# ATSAMG55G19 register map
Vendor: Atmel; Series: SAMG55; File version: 0
CPU: CM4 r0p1, selectable endian, MPU, FPU, 4 interrupt priority bits
Registers are 32-bit, read-write, reset 0x0 unless marked. A register's access mark holds for its fields unless they carry their own. Offsets are from the block's base; [hi:lo] are bit positions; {n}, {i} and the like mark numbered series; 'fields as' and 'values as' point back to an identical list.

## TC0 — Timer Counter 0
Base 0x40010000; register names take the prefix TC0_
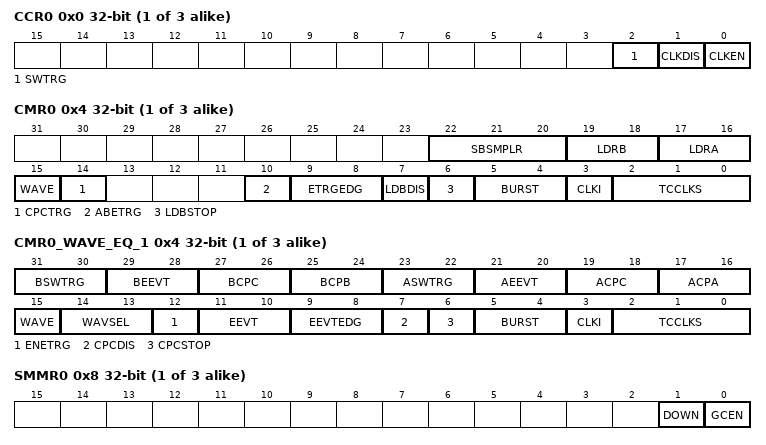
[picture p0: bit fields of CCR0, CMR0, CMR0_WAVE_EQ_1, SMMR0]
{0x0+0x40*i} CCR{i} wo reset not defined (i=0..2) — Channel Control Register (channel = {i})
  [2] SWTRG — Software Trigger Command
  [1] CLKDIS — Counter Clock Disable Command
  [0] CLKEN — Counter Clock Enable Command
{0x4+0x40*i} CMR{i} (i=0..2) — Channel Mode Register (channel = {i})
  [22:20] SBSMPLR — Loading Edge Subsampling Ratio
    0=ONE (Load a Capture Register each selected edge); 1=HALF (Load a Capture Register every 2 selected edges); 2=FOURTH (Load a Capture Register every 4 selected edges); 3=EIGHTH (Load a Capture Register every 8 selected edges); 4=SIXTEENTH (Load a Capture Register every 16 selected edges)
  [19:18] LDRB — RB Loading Edge Selection
    0=NONE; 1=RISING (Rising edge of TIOA); 2=FALLING (Falling edge of TIOA); 3=EDGE (Each edge of TIOA)
  [17:16] LDRA — RA Loading Edge Selection
    values as LDRB
  [15] WAVE — Waveform Mode
  [14] CPCTRG — RC Compare Trigger Enable
  [10] ABETRG — TIOA or TIOB External Trigger Selection
  [9:8] ETRGEDG — External Trigger Edge Selection
    0=NONE (The clock is not gated by an external signal.); 1=RISING (Rising edge); 2=FALLING (Falling edge); 3=EDGE (Each edge)
  [7] LDBDIS — Counter Clock Disable with RB Loading
  [6] LDBSTOP — Counter Clock Stopped with RB Loading
  [5:4] BURST — Burst Signal Selection
    0=NONE (The clock is not gated by an external signal.); 1=XC0 (XC0 is ANDed with the selected clock.); 2=XC1 (XC1 is ANDed with the selected clock.); 3=XC2 (XC2 is ANDed with the selected clock.)
  [3] CLKI — Clock Invert
  [2:0] TCCLKS — Clock Selection
    {v}=TIMER_CLOCK{v+1} (Clock selected: internal TIMER_CLOCK{v+1} clock signal (from PMC)) (v=0..4); 5=XC0 (Clock selected: XC0); 6=XC1 (Clock selected: XC1); 7=XC2 (Clock selected: XC2)
{0x4+0x40*i} CMR{i}_WAVE_EQ_1 (WAVE_EQ_1 view) (i=0..2) — Channel Mode Register (channel = {i})
  [31:30] BSWTRG — Software Trigger Effect on TIOB
    0=NONE; 1=SET; 2=CLEAR; 3=TOGGLE
  [29:28] BEEVT — External Event Effect on TIOB
    0=NONE; 1=SET; 2=CLEAR; 3=TOGGLE
  [27:26] BCPC — RC Compare Effect on TIOB
    0=NONE; 1=SET; 2=CLEAR; 3=TOGGLE
  [25:24] BCPB — RB Compare Effect on TIOB
    0=NONE; 1=SET; 2=CLEAR; 3=TOGGLE
  [23:22] ASWTRG — Software Trigger Effect on TIOA
    0=NONE; 1=SET; 2=CLEAR; 3=TOGGLE
  [21:20] AEEVT — External Event Effect on TIOA
    0=NONE; 1=SET; 2=CLEAR; 3=TOGGLE
  [19:18] ACPC — RC Compare Effect on TIOA
    0=NONE; 1=SET; 2=CLEAR; 3=TOGGLE
  [17:16] ACPA — RA Compare Effect on TIOA
    0=NONE; 1=SET; 2=CLEAR; 3=TOGGLE
  [15] WAVE — Waveform Mode
  [14:13] WAVSEL — Waveform Selection
    0=UP (UP mode without automatic trigger on RC Compare); 1=UPDOWN (UPDOWN mode without automatic trigger on RC Compare); 2=UP_RC (UP mode with automatic trigger on RC Compare); 3=UPDOWN_RC (UPDOWN mode with automatic trigger on RC Compare)
  [12] ENETRG — External Event Trigger Enable
  [11:10] EEVT — External Event Selection
    0=TIOB; 1=XC0; 2=XC1; 3=XC2
  [9:8] EEVTEDG — External Event Edge Selection
    0=NONE; 1=RISING (Rising edge); 2=FALLING (Falling edge); 3=EDGE (Each edge)
  [7] CPCDIS — Counter Clock Disable with RC Compare
  [6] CPCSTOP — Counter Clock Stopped with RC Compare
  [5:4] BURST — Burst Signal Selection
    values as CMR0.BURST
  [3] CLKI — Clock Invert
  [2:0] TCCLKS — Clock Selection
    values as CMR0.TCCLKS
{0x8+0x40*i} SMMR{i} (i=0..2) — Stepper Motor Mode Register (channel = {i})
  [1] DOWN — Down Count
  [0] GCEN — Gray Count Enable
{0xC+0x40*i} RAB{i} ro (i=0..2) — Register AB (channel = {i})
  [31:0] RAB — Register A or Register B
{0x10+0x40*i} CV{i} ro (i=0..2) — Counter Value (channel = {i})
  [31:0] CV — Counter Value
{0x14+0x40*i} RA{i} (i=0..2) — Register A (channel = {i})
  [31:0] RA — Register A
{0x18+0x40*i} RB{i} (i=0..2) — Register B (channel = {i})
  [31:0] RB — Register B
{0x1C+0x40*i} RC{i} (i=0..2) — Register C (channel = {i})
  [31:0] RC — Register C
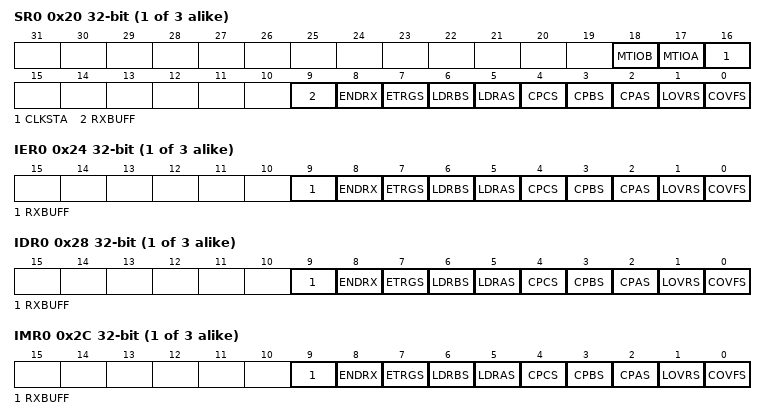
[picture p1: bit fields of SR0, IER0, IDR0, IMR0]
{0x20+0x40*i} SR{i} ro (i=0..2) — Status Register (channel = {i})
  [18] MTIOB — TIOB Mirror
  [17] MTIOA — TIOA Mirror
  [16] CLKSTA — Clock Enabling Status
  [9] RXBUFF — Reception Buffer Full (cleared by writing TC_RCR or TC_RNCR)
  [8] ENDRX — End of Receiver Transfer (cleared by writing TC_RCR or TC_RNCR)
  [7] ETRGS — External Trigger Status (cleared on read)
  [6] LDRBS — RB Loading Status (cleared on read)
  [5] LDRAS — RA Loading Status (cleared on read)
  [4] CPCS — RC Compare Status (cleared on read)
  [3] CPBS — RB Compare Status (cleared on read)
  [2] CPAS — RA Compare Status (cleared on read)
  [1] LOVRS — Load Overrun Status (cleared on read)
  [0] COVFS — Counter Overflow Status (cleared on read)
{0x24+0x40*i} IER{i} wo reset not defined (i=0..2) — Interrupt Enable Register (channel = {i})
  [9] RXBUFF — Reception Buffer Full
  [8] ENDRX — End of Receiver Transfer
  [7] ETRGS — External Trigger
  [6] LDRBS — RB Loading
  [5] LDRAS — RA Loading
  [4] CPCS — RC Compare
  [3] CPBS — RB Compare
  [2] CPAS — RA Compare
  [1] LOVRS — Load Overrun
  [0] COVFS — Counter Overflow
{0x28+0x40*i} IDR{i} wo reset not defined (i=0..2) — Interrupt Disable Register (channel = {i})
  fields as IER0
{0x2C+0x40*i} IMR{i} ro (i=0..2) — Interrupt Mask Register (channel = {i})
  fields as IER0
0xC0 BCR wo reset not defined — Block Control Register
  [0] SYNC — Synchro Command
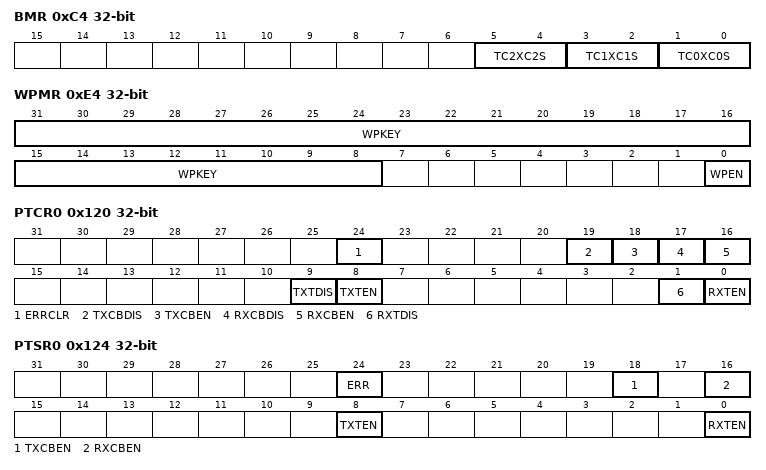
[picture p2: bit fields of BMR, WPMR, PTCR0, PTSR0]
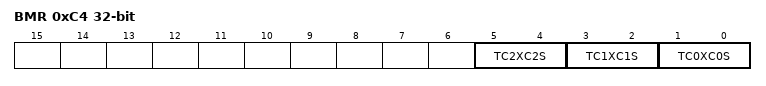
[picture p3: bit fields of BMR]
0xC4 BMR — Block Mode Register
  [5:4] TC2XC2S — External Clock Signal 2 Selection
    0=TCLK2 (Signal connected to XC2: TCLK2); 2=TIOA0 (Signal connected to XC2: TIOA0); 3=TIOA1 (Signal connected to XC2: TIOA1)
  [3:2] TC1XC1S — External Clock Signal 1 Selection
    0=TCLK1 (Signal connected to XC1: TCLK1); 2=TIOA0 (Signal connected to XC1: TIOA0); 3=TIOA2 (Signal connected to XC1: TIOA2)
  [1:0] TC0XC0S — External Clock Signal 0 Selection
    0=TCLK0 (Signal connected to XC0: TCLK0); 2=TIOA1 (Signal connected to XC0: TIOA1); 3=TIOA2 (Signal connected to XC0: TIOA2)
0xE4 WPMR — Write Protection Mode Register
  [31:8] WPKEY — Write Protection Key
    0x54494D=PASSWD (Writing any other value in this field aborts the write operation of the WPEN bit.Always reads as 0.)
  [0] WPEN — Write Protection Enable
0x100 RPR0 — Receive Pointer Register (pdc = 0)
  [31:0] RXPTR — Receive Pointer Register
0x104 RCR0 — Receive Counter Register (pdc = 0)
  [15:0] RXCTR — Receive Counter Register
0x110 RNPR0 — Receive Next Pointer Register (pdc = 0)
  [31:0] RXNPTR — Receive Next Pointer
0x114 RNCR0 — Receive Next Counter Register (pdc = 0)
  [15:0] RXNCTR — Receive Next Counter
0x120 PTCR0 wo reset not defined — Transfer Control Register (pdc = 0)
  [24] ERRCLR — Transfer Bus Error Clear
  [19] TXCBDIS — Transmitter Circular Buffer Disable
  [18] TXCBEN — Transmitter Circular Buffer Enable
  [17] RXCBDIS — Receiver Circular Buffer Disable
  [16] RXCBEN — Receiver Circular Buffer Enable
  [9] TXTDIS — Transmitter Transfer Disable
  [8] TXTEN — Transmitter Transfer Enable
  [1] RXTDIS — Receiver Transfer Disable
  [0] RXTEN — Receiver Transfer Enable
0x124 PTSR0 ro — Transfer Status Register (pdc = 0)
  [24] ERR — Transfer Bus Error
  [18] TXCBEN — Transmitter Circular Buffer Enable
  [16] RXCBEN — Receiver Circular Buffer Enable
  [8] TXTEN — Transmitter Transfer Enable
  [0] RXTEN — Receiver Transfer Enable

## TC1 — Timer Counter 1
Base 0x40014000; register names take the prefix TC1_
Registers as TC0, without RPR0, RCR0, RNPR0, RNCR0, PTCR0, PTSR0; these are added or differ:
0xC4 BMR — Block Mode Register
  fields as TC0.BMR
